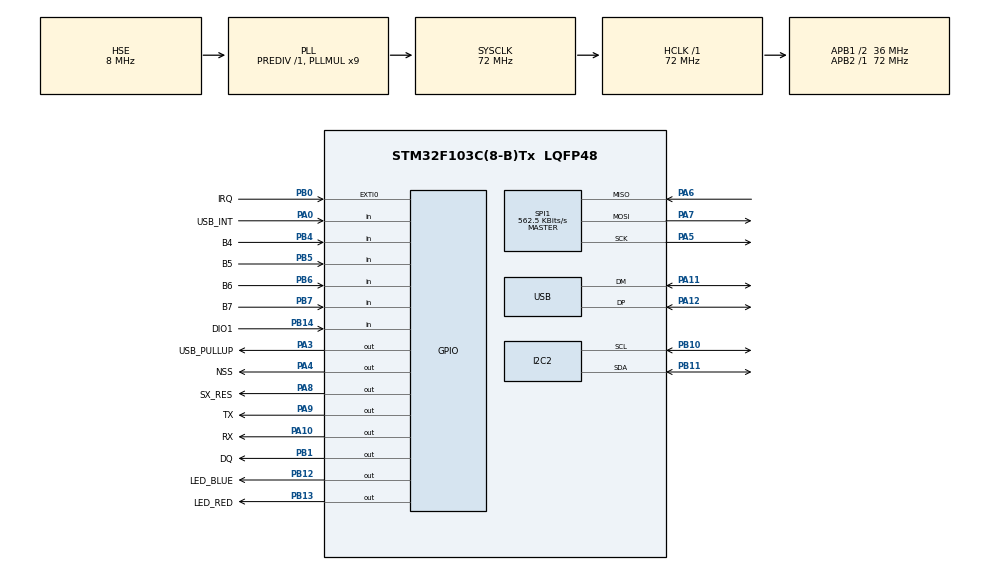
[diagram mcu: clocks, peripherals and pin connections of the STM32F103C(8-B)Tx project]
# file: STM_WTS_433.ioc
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Mcu.Family=STM32F1
Mcu.Name=STM32F103C(8-B)Tx
Mcu.Package=LQFP48
NVIC.EXTI0_IRQn=true\:0\:0\:false\:false\:true\:true\:true
NVIC.PriorityGroup=NVIC_PRIORITYGROUP_4
NVIC.TIM1_UP_IRQn=true\:0\:0\:false\:false\:true\:true\:true
NVIC.USB_LP_CAN1_RX0_IRQn=true\:0\:0\:false\:false\:true\:false\:true
PA0-WKUP.GPIO_Label=USB_INT
PA0-WKUP.GPIO_PuPd=GPIO_PULLDOWN
PA0-WKUP.Signal=GPIO_Input
PA10.GPIO_Label=RX
PA10.Signal=GPIO_Output
PA11.Mode=Device
PA11.Signal=USB_DM
PA12.Mode=Device
PA12.Signal=USB_DP
PA13.Mode=Trace_Asynchronous_SW
PA13.Signal=SYS_JTMS-SWDIO
PA14.Mode=Trace_Asynchronous_SW
PA14.Signal=SYS_JTCK-SWCLK
PA3.GPIO_Label=USB_PULLUP
PA3.Signal=GPIO_Output
PA4.GPIO_Label=NSS
PA4.Signal=GPIO_Output
PA5.Mode=Full_Duplex_Master
PA5.Signal=SPI1_SCK
PA6.Mode=Full_Duplex_Master
PA6.Signal=SPI1_MISO
PA7.Mode=Full_Duplex_Master
PA7.Signal=SPI1_MOSI
PA8.GPIO_Label=SX_RES
PA8.Signal=GPIO_Output
PA9.GPIO_Label=TX
PA9.GPIO_ModeDefaultOutputPP=GPIO_MODE_OUTPUT_OD
PA9.Signal=GPIO_Output
PB0.GPIO_Label=IRQ
PB0.GPIO_ModeDefaultEXTI=GPIO_MODE_IT_RISING
PB0.GPIO_PuPd=GPIO_NOPULL
PB0.Signal=GPXTI0
PB1.GPIO_Label=DQ
PB1.Signal=GPIO_Output
PB10.Mode=I2C
PB10.Signal=I2C2_SCL
PB11.Mode=I2C
PB11.Signal=I2C2_SDA
PB12.GPIO_Label=LED_BLUE
PB12.Signal=GPIO_Output
PB13.GPIO_Label=LED_RED
PB13.Signal=GPIO_Output
PB14.GPIO_Label=DIO1
PB14.Signal=GPIO_Input
PB3.Mode=Trace_Asynchronous_SW
PB3.Signal=SYS_JTDO-TRACESWO
PB4.GPIO_Label=B4
PB4.Signal=GPIO_Input
PB5.GPIO_Label=B5
PB5.Signal=GPIO_Input
PB6.GPIO_Label=B6
PB6.Signal=GPIO_Input
PB7.GPIO_Label=B7
PB7.Signal=GPIO_Input
PD0-OSC_IN.Mode=HSE-External-Oscillator
PD0-OSC_IN.Signal=RCC_OSC_IN
PD1-OSC_OUT.Mode=HSE-External-Oscillator
PD1-OSC_OUT.Signal=RCC_OSC_OUT
ProjectManager.HeapSize=0x800
ProjectManager.StackSize=0x800
ProjectManager.TargetToolchain=MDK-ARM V5.27
RCC.ADCPresc=RCC_ADCPCLK2_DIV8
RCC.AHBFreq_Value=72000000
RCC.APB1CLKDivider=RCC_HCLK_DIV2
RCC.APB1Freq_Value=36000000
RCC.APB1TimFreq_Value=72000000
RCC.APB2Freq_Value=72000000
RCC.APB2TimFreq_Value=72000000
RCC.HCLKFreq_Value=72000000
RCC.LSE_VALUE=32000
RCC.PLLMUL=RCC_PLL_MUL9
RCC.RTCClockSelection=RCC_RTCCLKSOURCE_LSE
RCC.SYSCLKFreq_VALUE=72000000
RCC.SYSCLKSource=RCC_SYSCLKSOURCE_PLLCLK
RCC.USBFreq_Value=48000000
RCC.USBPrescaler=RCC_USBCLKSOURCE_PLL_DIV1_5
SPI1.BaudRatePrescaler=SPI_BAUDRATEPRESCALER_128
SPI1.CalculateBaudRate=562.5 KBits/s
SPI1.Direction=SPI_DIRECTION_2LINES
SPI1.Mode=SPI_MODE_MASTER
SPI1.VirtualType=VM_MASTER
TIM1.ClockDivision=TIM_CLOCKDIVISION_DIV1
TIM1.Period=100
TIM1.Prescaler=35999
USB_DEVICE.APP_RX_DATA_SIZE=64
USB_DEVICE.APP_TX_DATA_SIZE=64
USB_DEVICE.CLASS_NAME_FS=CDC
USB_DEVICE.USBD_MAX_STR_DESC_SIZ=256
USB_DEVICE.VirtualMode=Cdc
USB_DEVICE.VirtualModeFS=Cdc_FS
VP_CRC_VS_CRC.Mode=CRC_Activate
VP_TIM1_VS_ClockSourceINT.Mode=Internal
VP_USB_DEVICE_VS_USB_DEVICE_CDC_FS.Mode=CDC_FS
board=STM_WTS

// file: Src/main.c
/* USER CODE BEGIN Header */
/**
  ******************************************************************************
  * @file           : main.c
  * @brief          : Main program body
  ******************************************************************************
  * @attention
  *
  * <h2><center>&copy; Copyright (c) 2020 STMicroelectronics.
  * All rights reserved.</center></h2>
  *
  * This software component is licensed by ST under Ultimate Liberty license
  * SLA0044, the "License"; You may not use this file except in compliance with
  * the License. You may obtain a copy of the License at:
  *                             www.st.com/SLA0044
  *
  ******************************************************************************
  */
/* USER CODE END Header */
#include "main.h"
#include "crc.h"
#include "i2c.h"
#include "spi.h"
#include "tim.h"
#include "usb_device.h"
#include "gpio.h"

/* USER CODE BEGIN Includes */
#include <stdio.h>

#include "usbd_cdc_if.h"
#include "uart_cmd_parser.h"
#include "SX1278.h"
#include "ds18b20.h"
#include "wireless_ctrl.h"
#include "sys_config.h"

/* USER CODE END Includes */

/* USER CODE BEGIN PV */
/* Private variables ---------------------------------------------------------*/

/* USER CODE END PV */

void SystemClock_Config(void);
/* USER CODE BEGIN PFP */
/* Private function prototypes -----------------------------------------------*/

/* USER CODE END PFP */

int main(void)
{

  /* MCU Configuration--------------------------------------------------------*/

  /* Reset of all peripherals, Initializes the Flash interface and the Systick. */
  HAL_Init();

  /* Configure the system clock */
  SystemClock_Config();

  /* Initialize all configured peripherals */
  MX_GPIO_Init();
  MX_SPI1_Init();
  MX_TIM1_Init();
  MX_CRC_Init();
  MX_USB_DEVICE_Init();
  MX_I2C2_Init();
  /* USER CODE BEGIN 2 */
	SysInit();
  /* USER CODE END 2 */

  /* Infinite loop */
  /* USER CODE BEGIN WHILE */

while (1){
	SystemTask();
    /* USER CODE END WHILE */

  }
}

void SystemClock_Config(void)
{
  RCC_OscInitTypeDef RCC_OscInitStruct = {0};
  RCC_ClkInitTypeDef RCC_ClkInitStruct = {0};
  RCC_PeriphCLKInitTypeDef PeriphClkInit = {0};

  /** Initializes the RCC Oscillators according to the specified parameters
  * in the RCC_OscInitTypeDef structure.
  */
  RCC_OscInitStruct.OscillatorType = RCC_OSCILLATORTYPE_HSE;
  RCC_OscInitStruct.HSEState = RCC_HSE_ON;
  RCC_OscInitStruct.HSEPredivValue = RCC_HSE_PREDIV_DIV1;
  RCC_OscInitStruct.HSIState = RCC_HSI_ON;
  RCC_OscInitStruct.PLL.PLLState = RCC_PLL_ON;
  RCC_OscInitStruct.PLL.PLLSource = RCC_PLLSOURCE_HSE;
  RCC_OscInitStruct.PLL.PLLMUL = RCC_PLL_MUL9;
  if (HAL_RCC_OscConfig(&RCC_OscInitStruct) != HAL_OK)
  {
    Error_Handler();
  }
  /** Initializes the CPU, AHB and APB buses clocks
  */
  RCC_ClkInitStruct.ClockType = RCC_CLOCKTYPE_HCLK|RCC_CLOCKTYPE_SYSCLK
                              |RCC_CLOCKTYPE_PCLK1|RCC_CLOCKTYPE_PCLK2;
  RCC_ClkInitStruct.SYSCLKSource = RCC_SYSCLKSOURCE_PLLCLK;
  RCC_ClkInitStruct.AHBCLKDivider = RCC_SYSCLK_DIV1;
  RCC_ClkInitStruct.APB1CLKDivider = RCC_HCLK_DIV2;
  RCC_ClkInitStruct.APB2CLKDivider = RCC_HCLK_DIV1;

  if (HAL_RCC_ClockConfig(&RCC_ClkInitStruct, FLASH_LATENCY_2) != HAL_OK)
  {
    Error_Handler();
  }
  PeriphClkInit.PeriphClockSelection = RCC_PERIPHCLK_USB;
  PeriphClkInit.UsbClockSelection = RCC_USBCLKSOURCE_PLL_DIV1_5;
  if (HAL_RCCEx_PeriphCLKConfig(&PeriphClkInit) != HAL_OK)
  {
    Error_Handler();
  }
}

void Error_Handler(void)
{
  while(1)
  {
  }
}

/************************ (C) COPYRIGHT STMicroelectronics *****END OF FILE****/
